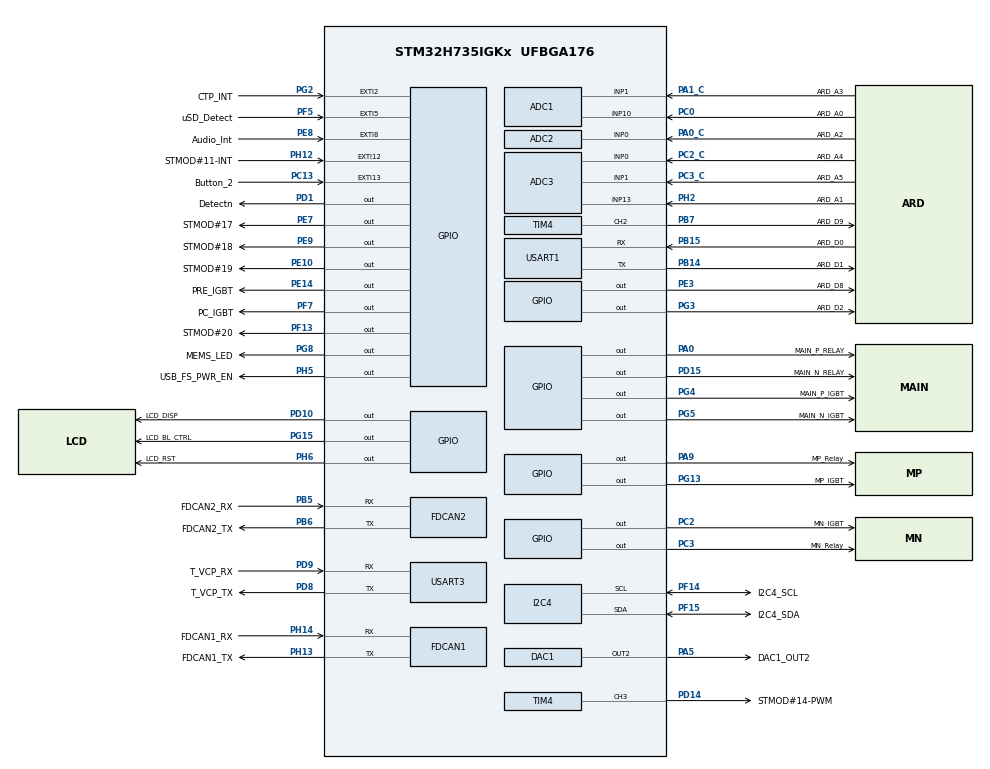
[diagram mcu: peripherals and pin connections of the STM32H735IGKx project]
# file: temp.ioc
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ADC1.Channel-1\#ChannelRegularConversion=ADC_CHANNEL_1
ADC1.NbrOfConversionFlag=1
ADC1.OffsetNumber-1\#ChannelRegularConversion=ADC_OFFSET_NONE
ADC1.OffsetSignedSaturation-1\#ChannelRegularConversion=DISABLE
ADC1.Rank-1\#ChannelRegularConversion=1
ADC1.SamplingTime-1\#ChannelRegularConversion=ADC_SAMPLETIME_1CYCLE_5
ADC1.master=1
ADC2.Channel-0\#ChannelRegularConversion=ADC_CHANNEL_0
ADC2.NbrOfConversionFlag=1
ADC2.OffsetNumber-0\#ChannelRegularConversion=ADC_OFFSET_NONE
ADC2.OffsetSignedSaturation-0\#ChannelRegularConversion=DISABLE
ADC2.Rank-0\#ChannelRegularConversion=1
ADC2.SamplingTime-0\#ChannelRegularConversion=ADC_SAMPLETIME_1CYCLE_5
ADC3.Channel-2\#ChannelRegularConversion=ADC_CHANNEL_0
ADC3.NbrOfConversionFlag=1
ADC3.OffsetNumber-2\#ChannelRegularConversion=ADC_OFFSET_NONE
ADC3.OffsetSaturation-2\#ChannelRegularConversion=DISABLE
ADC3.OffsetSign-2\#ChannelRegularConversion=ADC3_OFFSET_SIGN_NEGATIVE
ADC3.OffsetSignedSaturation-2\#ChannelRegularConversion=DISABLE
ADC3.Rank-2\#ChannelRegularConversion=1
ADC3.SamplingTime-2\#ChannelRegularConversion=ADC3_SAMPLETIME_2CYCLES_5
DAC1.DAC_Channel-DAC_OUT2=DAC_CHANNEL_2
I2C4.Timing=0x60404E72
Mcu.Family=STM32H7
Mcu.Name=STM32H735IGKx
Mcu.Package=UFBGA176
NVIC.EXTI15_10_IRQn=true\:0\:0\:false\:false\:true\:true\:true
NVIC.PriorityGroup=NVIC_PRIORITYGROUP_4
NVIC.TIM16_IRQn=true\:0\:0\:false\:false\:true\:true\:true
NVIC.TIM17_IRQn=true\:0\:0\:false\:false\:true\:true\:true
NVIC.TIM7_IRQn=true\:0\:0\:false\:false\:true\:true\:true
NVIC.TIM8_UP_TIM13_IRQn=true\:0\:0\:false\:false\:true\:true\:true
PA0.GPIO_Label=MAIN_P_RELAY
PA0.Signal=GPIO_Output
PA0_C.GPIO_Label=ARD_A2
PA0_C.Signal=ADCx_INP0
PA1.GPIO_Label=RMII_REF_CLK
PA1.GPIO_Speed=GPIO_SPEED_FREQ_LOW
PA1.Signal=ETH_REF_CLK
PA10.GPIO_Label=USB_FS_ID
PA10.Signal=USB_OTG_HS_ID
PA11.GPIO_Label=USB_FS_DM
PA11.Signal=USB_OTG_HS_DM
PA12.GPIO_Label=USB_FS_DP
PA12.Signal=USB_OTG_HS_DP
PA13(JTMS/SWDIO).GPIO_Label=JTMS
PA13(JTMS/SWDIO).Mode=JTAG_5_pins
PA13(JTMS/SWDIO).Signal=DEBUG_JTMS-SWDIO
PA14(JTCK/SWCLK).GPIO_Label=JTCK
PA14(JTCK/SWCLK).Mode=JTAG_5_pins
PA14(JTCK/SWCLK).Signal=DEBUG_JTCK-SWCLK
PA15(JTDI).GPIO_Label=JTDI
PA15(JTDI).Mode=JTAG_5_pins
PA15(JTDI).Signal=DEBUG_JTDI
PA1_C.GPIO_Label=ARD_A3
PA1_C.Signal=ADCx_INP1
PA2.GPIO_Label=RMII_MDIO
PA2.GPIO_Speed=GPIO_SPEED_FREQ_LOW
PA2.Signal=ETH_MDIO
PA3.GPIO_Label=LCD_B5
PA3.GPIO_Speed=GPIO_SPEED_FREQ_LOW
PA3.Signal=LTDC_B5
PA4.GPIO_Label=LCD_VSYNC
PA4.GPIO_Speed=GPIO_SPEED_FREQ_LOW
PA4.Signal=LTDC_VSYNC
PA5.GPIO_Label=DAC1_OUT2
PA5.Signal=COMP_DAC12_group
PA7.GPIO_Label=RMII_CRS_DV
PA7.GPIO_Speed=GPIO_SPEED_FREQ_LOW
PA7.Signal=ETH_CRS_DV
PA8.GPIO_Label=LCD_B3
PA8.GPIO_Speed=GPIO_SPEED_FREQ_LOW
PA8.Signal=LTDC_B3
PA9.GPIO_Label=MP_Relay
PA9.Signal=GPIO_Output
PB0.GPIO_Label=LCD_G1
PB0.GPIO_Speed=GPIO_SPEED_FREQ_LOW
PB0.Signal=LTDC_G1
PB1.GPIO_Label=LCD_G0
PB1.GPIO_Speed=GPIO_SPEED_FREQ_LOW
PB1.Signal=LTDC_G0
PB10.GPIO_Label=RMII_RX_ER
PB10.Signal=ETH_RX_ER
PB11.GPIO_Label=RMII_TX_EN
PB11.GPIO_Speed=GPIO_SPEED_FREQ_LOW
PB11.Signal=ETH_TX_EN
PB12.GPIO_Label=RMII_TXD0
PB12.GPIO_Speed=GPIO_SPEED_FREQ_LOW
PB12.Signal=ETH_TXD0
PB13.GPIO_Label=RMII_TXD1
PB13.GPIO_Speed=GPIO_SPEED_FREQ_LOW
PB13.Signal=ETH_TXD1
PB14.GPIO_Label=ARD_D1
PB14.GPIO_PuPd=GPIO_NOPULL
PB14.Mode=Asynchronous
PB14.Signal=USART1_TX
PB15.GPIO_Label=ARD_D0
PB15.GPIO_PuPd=GPIO_NOPULL
PB15.Mode=Asynchronous
PB15.Signal=USART1_RX
PB2.GPIO_Label=OCSPI1_DQS
PB2.Signal=OCTOSPIM_P1_DQS
PB3(JTDO/TRACESWO).GPIO_Label=JTDO
PB3(JTDO/TRACESWO).Mode=JTAG_5_pins
PB3(JTDO/TRACESWO).Signal=DEBUG_JTDO-SWO
PB4(NJTRST).GPIO_Label=NJTRST
PB4(NJTRST).Mode=JTAG_5_pins
PB4(NJTRST).Signal=DEBUG_JTRST
PB5.GPIO_Label=FDCAN2_RX
PB5.Mode=FDCAN_Activate
PB5.Signal=FDCAN2_RX
PB6.GPIO_Label=FDCAN2_TX
PB6.Mode=FDCAN_Activate
PB6.Signal=FDCAN2_TX
PB7.GPIO_Label=ARD_D9
PB7.Signal=S_TIM4_CH2
PB8.GPIO_Label=LCD_B6
PB8.GPIO_Speed=GPIO_SPEED_FREQ_LOW
PB8.Signal=LTDC_B6
PB9.GPIO_Label=LCD_B7
PB9.GPIO_Speed=GPIO_SPEED_FREQ_LOW
PB9.Signal=LTDC_B7
PC0.GPIO_Label=ARD_A0
PC0.Signal=ADCx_INP10
PC1.GPIO_Label=RMII_MDC
PC1.GPIO_Speed=GPIO_SPEED_FREQ_LOW
PC1.Signal=ETH_MDC
PC10.GPIO_Label=SDIO1_D2
PC10.Signal=SDMMC1_D2
PC11.GPIO_Label=SDIO1_D3
PC11.Signal=SDMMC1_D3
PC12.GPIO_Label=SDIO1_CK
PC12.Signal=SDMMC1_CK
PC13.GPIO_Label=Button_2
PC13.Signal=GPXTI13
PC14-OSC32_IN.Mode=LSE-External-Oscillator
PC14-OSC32_IN.Signal=RCC_OSC32_IN
PC15-OSC32_OUT.Mode=LSE-External-Oscillator
PC15-OSC32_OUT.Signal=RCC_OSC32_OUT
PC2.GPIO_Label=MN_IGBT
PC2.Signal=GPIO_Output
PC2_C.GPIO_Label=ARD_A4
PC2_C.Mode=IN0-Single-Ended
PC2_C.Signal=ADC3_INP0
PC3.GPIO_Label=MN_Relay
PC3.Signal=GPIO_Output
PC3_C.GPIO_Label=ARD_A5
PC3_C.Mode=IN1-Single-Ended
PC3_C.Signal=ADC3_INP1
PC4.GPIO_Label=RMII_RXD0
PC4.GPIO_Speed=GPIO_SPEED_FREQ_LOW
PC4.Signal=ETH_RXD0
PC5.GPIO_Label=RMII_RXD1
PC5.GPIO_Speed=GPIO_SPEED_FREQ_LOW
PC5.Signal=ETH_RXD1
PC6.GPIO_Label=LCD_HSYNC
PC6.GPIO_Speed=GPIO_SPEED_FREQ_LOW
PC6.Signal=LTDC_HSYNC
PC7.GPIO_Label=LCD_G6
PC7.GPIO_Speed=GPIO_SPEED_FREQ_LOW
PC7.Signal=LTDC_G6
PC8.GPIO_Label=SDIO1_D0
PC8.Signal=SDMMC1_D0
PC9.GPIO_Label=SDIO1_D1
PC9.Signal=SDMMC1_D1
PD0.GPIO_Label=LCD_B1
PD0.GPIO_Speed=GPIO_SPEED_FREQ_LOW
PD0.Signal=LTDC_B1
PD1.GPIO_Label=Detectn
PD1.GPIO_PuPd=GPIO_NOPULL
PD1.Signal=GPIO_Output
PD10.GPIO_Label=LCD_DISP
PD10.GPIO_Speed=GPIO_SPEED_FREQ_LOW
PD10.Signal=GPIO_Output
PD11.GPIO_Label=OCSPI1_IO0
PD11.Signal=OCTOSPIM_P1_IO0
PD12.GPIO_Label=OCSPI1_IO1
PD12.Signal=OCTOSPIM_P1_IO1
PD13.GPIO_Label=OCSPI1_IO3
PD13.Signal=OCTOSPIM_P1_IO3
PD14.GPIO_Label=STMOD\#14-PWM
PD14.Signal=S_TIM4_CH3
PD15.GPIO_Label=MAIN_N_RELAY
PD15.Signal=GPIO_Output
PD2.GPIO_Label=SDIO1_CMD
PD2.Signal=SDMMC1_CMD
PD3.GPIO_Label=LCD_G7
PD3.GPIO_Speed=GPIO_SPEED_FREQ_LOW
PD3.Signal=LTDC_G7
PD4.GPIO_Label=OCSPI1_IO4
PD4.Signal=OCTOSPIM_P1_IO4
PD5.GPIO_Label=OCSPI1_IO5
PD5.Signal=OCTOSPIM_P1_IO5
PD6.GPIO_Label=LCD_B2
PD6.GPIO_Speed=GPIO_SPEED_FREQ_LOW
PD6.Signal=LTDC_B2
PD7.GPIO_Label=OCSPI1_IO7
PD7.Signal=OCTOSPIM_P1_IO7
PD8.GPIO_Label=T_VCP_TX
PD8.GPIO_PuPd=GPIO_NOPULL
PD8.Mode=Asynchronous
PD8.Signal=USART3_TX
PD9.GPIO_Label=T_VCP_RX
PD9.GPIO_PuPd=GPIO_NOPULL
PD9.Mode=Asynchronous
PD9.Signal=USART3_RX
PE0.GPIO_Label=LCD_R0
PE0.GPIO_Speed=GPIO_SPEED_FREQ_LOW
PE0.Signal=LTDC_R0
PE1.GPIO_Label=LCD_R6
PE1.GPIO_Speed=GPIO_SPEED_FREQ_LOW
PE1.Signal=LTDC_R6
PE10.GPIO_Label=STMOD\#19
PE10.Signal=GPIO_Output
PE11.GPIO_Label=LCD_G3
PE11.GPIO_Speed=GPIO_SPEED_FREQ_LOW
PE11.Signal=LTDC_G3
PE12.GPIO_Label=LCD_B4
PE12.GPIO_Speed=GPIO_SPEED_FREQ_LOW
PE12.Signal=LTDC_B4
PE13.GPIO_Label=LCD_DE
PE13.GPIO_Speed=GPIO_SPEED_FREQ_LOW
PE13.Signal=LTDC_DE
PE14.GPIO_Label=PRE_IGBT
PE14.Signal=GPIO_Output
PE15.GPIO_Label=LCD_R7
PE15.GPIO_Speed=GPIO_SPEED_FREQ_LOW
PE15.Signal=LTDC_R7
PE2.GPIO_Label=OCSPI1_IO2
PE2.Signal=OCTOSPIM_P1_IO2
PE3.GPIO_Label=ARD_D8
PE3.Signal=GPIO_Output
PE4.GPIO_Label=SAI4_D2
PE4.Signal=SAI4_D2
PE5.GPIO_Label=SAI4_CK2
PE5.Signal=SAI4_CK2
PE6.GPIO_Label=SAI1_SD_A
PE6.Signal=SAI1_SD_A
PE7.GPIO_Label=STMOD\#17
PE7.Signal=GPIO_Output
PE8.GPIO_Label=Audio_Int
PE8.Signal=GPXTI8
PE9.GPIO_Label=STMOD\#18
PE9.Signal=GPIO_Output
PF0.GPIO_Label=OCSPI2_IO0
PF0.Signal=OCTOSPIM_P2_IO0
PF1.GPIO_Label=OCSPI2_IO1
PF1.Signal=OCTOSPIM_P2_IO1
PF10.GPIO_Label=OCSPI1_CLK
PF10.Signal=OCTOSPIM_P1_CLK
PF11.GPIO_Label=SPI5_MOSI
PF11.Signal=SPI5_MOSI
PF12.GPIO_Label=OCSPI2_DQS
PF12.Signal=OCTOSPIM_P2_DQS
PF13.GPIO_Label=STMOD\#20
PF13.Signal=GPIO_Output
PF14.GPIO_Label=I2C4_SCL
PF14.GPIO_Pu=GPIO_PULLUP
PF14.Mode=I2C
PF14.Signal=I2C4_SCL
PF15.GPIO_Label=I2C4_SDA
PF15.GPIO_Pu=GPIO_PULLUP
PF15.Mode=I2C
PF15.Signal=I2C4_SDA
PF2.GPIO_Label=OCSPI2_IO2
PF2.Signal=OCTOSPIM_P2_IO2
PF3.GPIO_Label=OCSPI2_IO3
PF3.Signal=OCTOSPIM_P2_IO3
PF4.GPIO_Label=OCSPI2_CLK
PF4.Signal=OCTOSPIM_P2_CLK
PF5.GPIO_Label=uSD_Detect
PF5.Signal=GPXTI5
PF6.GPIO_Label=SAI1_SD_B
PF6.Signal=SAI1_SD_B
PF7.GPIO_Label=PC_IGBT
PF7.Signal=GPIO_Output
PF8.GPIO_Label=SAI1_SCK_B
PF8.Signal=SAI1_SCK_B
PF9.GPIO_Label=SAI1_FS_B
PF9.Signal=SAI1_FS_B
PG0.GPIO_Label=OCSPI2_IO4
PG0.Signal=OCTOSPIM_P2_IO4
PG1.GPIO_Label=OCSPI2_IO5
PG1.Signal=OCTOSPIM_P2_IO5
PG10.GPIO_Label=OCSPI2_IO6
PG10.Signal=OCTOSPIM_P2_IO6
PG11.GPIO_Label=OCSPI2_IO7
PG11.Signal=OCTOSPIM_P2_IO7
PG12.GPIO_Label=OCSPI2_NCS
PG12.Signal=OCTOSPIM_P2_NCS
PG13.GPIO_Label=MP_IGBT
PG13.Signal=GPIO_Output
PG14.GPIO_Label=LCD_B0
PG14.GPIO_Speed=GPIO_SPEED_FREQ_LOW
PG14.Signal=LTDC_B0
PG15.GPIO_Label=LCD_BL_CTRL
PG15.GPIO_Speed=GPIO_SPEED_FREQ_LOW
PG15.Signal=GPIO_Output
PG2.GPIO_Label=CTP_INT
PG2.Signal=GPXTI2
PG3.GPIO_Label=ARD_D2
PG3.Signal=GPIO_Output
PG4.GPIO_Label=MAIN_P_IGBT
PG4.Signal=GPIO_Output
PG5.GPIO_Label=MAIN_N_IGBT
PG5.Signal=GPIO_Output
PG6.GPIO_Label=OCSPI1_NCS
PG6.Signal=OCTOSPIM_P1_NCS
PG7.GPIO_Label=LCD_CLK
PG7.GPIO_Speed=GPIO_SPEED_FREQ_LOW
PG7.Signal=LTDC_CLK
PG8.GPIO_Label=MEMS_LED
PG8.Signal=GPIO_Output
PG9.GPIO_Label=OCSPI1_IO6
PG9.Signal=OCTOSPIM_P1_IO6
PH0-OSC_IN.Mode=HSE-External-Oscillator
PH0-OSC_IN.Signal=RCC_OSC_IN
PH1-OSC_OUT.Mode=HSE-External-Oscillator
PH1-OSC_OUT.Signal=RCC_OSC_OUT
PH10.GPIO_Label=LCD_R4
PH10.GPIO_Speed=GPIO_SPEED_FREQ_LOW
PH10.Signal=LTDC_R4
PH11.GPIO_Label=LCD_R5
PH11.GPIO_Speed=GPIO_SPEED_FREQ_LOW
PH11.Signal=LTDC_R5
PH12.GPIO_Label=STMOD\#11-INT
PH12.Signal=GPXTI12
PH13.GPIO_Label=FDCAN1_TX
PH13.Mode=FDCAN_Activate
PH13.Signal=FDCAN1_TX
PH14.GPIO_Label=FDCAN1_RX
PH14.Mode=FDCAN_Activate
PH14.Signal=FDCAN1_RX
PH15.GPIO_Label=LCD_G4
PH15.GPIO_Speed=GPIO_SPEED_FREQ_LOW
PH15.Signal=LTDC_G4
PH2.GPIO_Label=ARD_A1
PH2.Mode=IN13-Single-Ended
PH2.Signal=ADC3_INP13
PH3.GPIO_Label=LCD_R1
PH3.GPIO_Speed=GPIO_SPEED_FREQ_LOW
PH3.Signal=LTDC_R1
PH4.GPIO_Label=LCD_G5
PH4.GPIO_Speed=GPIO_SPEED_FREQ_LOW
PH4.Signal=LTDC_G5
PH5.GPIO_Label=USB_FS_PWR_EN
PH5.Signal=GPIO_Output
PH6.GPIO_Label=LCD_RST
PH6.GPIO_Speed=GPIO_SPEED_FREQ_LOW
PH6.Signal=GPIO_Output
PH7.GPIO_Label=SPI5_MISO
PH7.Signal=SPI5_MISO
PH8.GPIO_Label=LCD_R2
PH8.GPIO_Speed=GPIO_SPEED_FREQ_LOW
PH8.Signal=LTDC_R2
PH9.GPIO_Label=LCD_R3
PH9.GPIO_Speed=GPIO_SPEED_FREQ_LOW
PH9.Signal=LTDC_R3
ProjectManager.HeapSize=0x200
ProjectManager.StackSize=0x400
ProjectManager.TargetToolchain=STM32CubeIDE
RCC.ADCFreq_Value=80000000
RCC.APB1Freq_Value=137500000
RCC.APB2Freq_Value=137500000
RCC.APB3Freq_Value=137500000
RCC.APB4Freq_Value=137500000
RCC.CortexFreq_Value=550000000
RCC.D1PPRE=RCC_APB3_DIV2
RCC.D2PPRE1=RCC_APB1_DIV2
RCC.D2PPRE2=RCC_APB2_DIV2
RCC.D3PPRE=RCC_APB4_DIV2
RCC.DIVM1=5
RCC.DIVM2=5
RCC.DIVN1=110
RCC.DIVN2=80
RCC.DIVP1=1
RCC.DIVP2=5
RCC.DIVQ1=4
RCC.HCLKFreq_Value=275000000
RCC.HPRE=RCC_HCLK_DIV2
RCC.PLL2FRACN=0
RCC.PLL3FRACN=0
RCC.PLLFRACN=0
RCC.PLLSourceVirtual=RCC_PLLSOURCE_HSE
RCC.SYSCLKFreq_VALUE=550000000
RCC.SYSCLKSource=RCC_SYSCLKSOURCE_PLLCLK
RCC.USBCLockSelection=RCC_USBCLKSOURCE_HSI48
RCC.USBFreq_Value=48000000
RTC.Date=10
RTC.Hours=22
RTC.Minutes=22
RTC.Month=RTC_MONTH_FEBRUARY
RTC.Seconds=22
RTC.WeekDay=RTC_WEEKDAY_THURSDAY
RTC.Year=22
SH.ADCx_INP0.0=ADC1_INP0
SH.ADCx_INP0.1=ADC2_INP0,IN0-Single-Ended
SH.ADCx_INP1.0=ADC2_INP1
SH.ADCx_INP1.1=ADC1_INP1,IN1-Single-Ended
SH.ADCx_INP10.0=ADC1_INP10,IN10-Single-Ended
SH.COMP_DAC12_group.0=DAC1_OUT2,DAC_OUT2
SH.S_TIM4_CH2.0=TIM4_CH2,PWM Generation2 CH2
SH.S_TIM4_CH3.0=TIM4_CH3,PWM Generation3 CH3
TIM13.Period=1500-1
TIM13.Prescaler=27500 -1
TIM14.Prescaler=2750-1
TIM16.Period=3500-1
TIM16.Prescaler=27500-1
TIM17.Period=5000-1
TIM17.Prescaler=27500-1
TIM4.Channel-PWM\ Generation2\ CH2=TIM_CHANNEL_2
TIM4.Channel-PWM\ Generation3\ CH3=TIM_CHANNEL_3
TIM7.Period=500-1
TIM7.Prescaler=27500-1
USART1.VirtualMode-Asynchronous=VM_ASYNC
USART3.VirtualMode-Asynchronous=VM_ASYNC
VP_RTC_VS_RTC_Activate.Mode=RTC_Enabled
VP_RTC_VS_RTC_Calendar.Mode=RTC_Calendar
VP_TIM13_VS_ClockSourceINT.Mode=Enable_Timer
VP_TIM14_VS_ClockSourceINT.Mode=Enable_Timer
VP_TIM16_VS_ClockSourceINT.Mode=Enable_Timer
VP_TIM17_VS_ClockSourceINT.Mode=Enable_Timer
VP_TIM7_VS_ClockSourceINT.Mode=Enable_Timer
board=STM32H735G-DK

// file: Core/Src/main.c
/* USER CODE BEGIN Header */
/**
  ******************************************************************************
  * @file           : main.c
  * @brief          : Main program body
  ******************************************************************************
  * @attention
  *
  * <h2><center>&copy; Copyright (c) 2022 STMicroelectronics.
  * All rights reserved.</center></h2>
  *
  * This software component is licensed by ST under BSD 3-Clause license,
  * the "License"; You may not use this file except in compliance with the
  * License. You may obtain a copy of the License at:
  *                        opensource.org/licenses/BSD-3-Clause
  *
  ******************************************************************************
  */
/* USER CODE END Header */
#include "main.h"

/* USER CODE BEGIN PD */
#ifdef __GNUC__
/* With GCC, small printf (option LD Linker->Libraries->Small printf
   set to 'Yes') calls __io_putchar() */
#define PUTCHAR_PROTOTYPE int __io_putchar(int ch)
#else
#define PUTCHAR_PROTOTYPE int fputc(int ch, FILE *f)
#endif /* __GNUC__ */

#define FIX_TIMER_TRIGGER(handle_ptr) (__HAL_TIM_CLEAR_FLAG(handle_ptr, TIM_SR_UIF))

#define MN_ON 0
#define MP_ON 1
#define OFF 2
/* USER CODE END PD */

ADC_HandleTypeDef hadc1;
ADC_HandleTypeDef hadc2;
ADC_HandleTypeDef hadc3;

DAC_HandleTypeDef hdac1;

FDCAN_HandleTypeDef hfdcan1;
FDCAN_HandleTypeDef hfdcan2;

I2C_HandleTypeDef hi2c4;

RTC_HandleTypeDef hrtc;

TIM_HandleTypeDef htim4;
TIM_HandleTypeDef htim7;
TIM_HandleTypeDef htim13;
TIM_HandleTypeDef htim14;
TIM_HandleTypeDef htim16;
TIM_HandleTypeDef htim17;

UART_HandleTypeDef huart1;
UART_HandleTypeDef huart3;

/* USER CODE BEGIN PV */
PUTCHAR_PROTOTYPE
{
  /* Place your implementation of fputc here */
  /* e.g. write a character to the USART1 and Loop until the end of transmission */
  HAL_UART_Transmit(&huart3, (uint8_t *)&ch, 1, 0xFFFF);

  return ch;
}

//volatile unsigned int timing_counter = 0; // for timing control in autostart, stop

// status variables
int tim7_status; // check if mp relay on/mn relay on/mp,mn relay off
int signal_status = 1; // check if on(auto_start)/off(stop) signal

// variables for printing the timing logs
uint32_t timestamp[2000][2];
uint32_t id = 0; // timestamp arr index

/* USER CODE END PV */

void SystemClock_Config(void);
void PeriphCommonClock_Config(void);
static void MX_GPIO_Init(void);
static void MX_ADC1_Init(void);
static void MX_ADC2_Init(void);
static void MX_ADC3_Init(void);
static void MX_DAC1_Init(void);
static void MX_FDCAN1_Init(void);
static void MX_FDCAN2_Init(void);
static void MX_I2C4_Init(void);
static void MX_TIM4_Init(void);
static void MX_USART1_UART_Init(void);
static void MX_USART3_UART_Init(void);
static void MX_TIM13_Init(void);
static void MX_RTC_Init(void);
static void MX_TIM14_Init(void);
static void MX_TIM7_Init(void);
static void MX_TIM16_Init(void);
static void MX_TIM17_Init(void);

/* USER CODE BEGIN 0 */

// save current tim14 cnt with given sequence step(x)
void save_timestamp(int x){
	timestamp[id][0] = x;
	timestamp[id][1] = TIM14->CNT / 100;
	//timestamp[id] = uwTick;
	id++;
}

// print the timestamps saved before
void print_timestamp(){
	int i, tmp;
	int k = 0;
	i = 0;
	for (i=0; i<id; i++){
		// when cnt is overflowed
		if (timestamp[i][1] <= timestamp[i-1][1])
			tmp = 65535 + timestamp[i][1] - timestamp[i-1][1];
		else
			tmp = timestamp[i][1] - timestamp[i-1][1];
		printf("(%d) %ld ms ellapsed after prev timestamp. \r\n", timestamp[i][0], tmp);
		printf("--------------------\r\n");
	}

}

//void autostart(){
//	if(timing_counter == 0){
//		HAL_GPIO_WritePin(GPIOC, MN_IGBT_Pin, RESET);
//		TIM14->CNT = 0;
//		HAL_TIM_Base_Start(&htim14);
//	}
//	else if(timing_counter == 1){
//		HAL_GPIO_WritePin(GPIOC, MN_Relay_Pin, RESET);
//		save_timestamp();
//	}
//	else if(timing_counter == 10){
//		HAL_GPIO_WritePin(GPIOF, PC_IGBT_Pin, SET);
//		save_timestamp();
//	}
//	else if(timing_counter == 20){
//		HAL_GPIO_WritePin(GPIOG, MP_IGBT_Pin, RESET);
//		save_timestamp();
//	}
//	else if(timing_counter == 21){
//		HAL_GPIO_WritePin(GPIOA, MP_Relay_Pin, SET);
//		save_timestamp();
//	}
//	else if(timing_counter == 30){
//		HAL_GPIO_WritePin(GPIOF, PC_IGBT_Pin, RESET);
//		save_timestamp();
//		HAL_TIM_Base_Stop_IT(&htim13);
//		HAL_TIM_Base_Stop(&htim14);
//		timing_counter = -1;
//		print_timestamp();
//		id = 0;
//	}
//	timing_counter += 1;
//}

// timers interrupt handler routine
void HAL_TIM_PeriodElapsedCallback(TIM_HandleTypeDef *htim)
{
	if (htim->Instance == TIM7){
		switch(tim7_status){
			case MN_ON: // mn relay on
				HAL_TIM_Base_Stop_IT(&htim7);
				HAL_GPIO_WritePin(GPIOC, MN_Relay_Pin, RESET);
				HAL_GPIO_WritePin(MAIN_N_RELAY_GPIO_Port, MAIN_N_RELAY_Pin, SET);
				save_timestamp(0);
				tim7_status = MP_ON; // toggle timer status
				break;
			case MP_ON: // mp relay on
				HAL_TIM_Base_Stop_IT(&htim7);
				HAL_GPIO_WritePin(GPIOA, MP_Relay_Pin, SET);
				HAL_GPIO_WritePin(MAIN_P_RELAY_GPIO_Port, MAIN_P_RELAY_Pin, SET);
				save_timestamp(3);
				break;
			case OFF: // mn, mp igbt off
				HAL_TIM_Base_Stop_IT(&htim7);
				HAL_GPIO_WritePin(GPIOC, MN_IGBT_Pin, SET);
				HAL_GPIO_WritePin(MAIN_N_IGBT_GPIO_Port, MAIN_N_IGBT_Pin, RESET);
				HAL_GPIO_WritePin(GPIOG, MP_IGBT_Pin, SET);
				HAL_GPIO_WritePin(MAIN_P_IGBT_GPIO_Port, MAIN_P_IGBT_Pin, RESET);

				save_timestamp(5);
				HAL_TIM_Base_Stop(&htim14);
				print_timestamp();
				id = 0; // reset the timestamp id
		}

	}
	else if (htim->Instance == TIM13){ // pc igbt on
		HAL_TIM_Base_Stop_IT(&htim13);
		HAL_GPIO_WritePin(GPIOF, PC_IGBT_Pin, SET);
		HAL_GPIO_WritePin(PRE_IGBT_GPIO_Port, PRE_IGBT_Pin, SET);

		save_timestamp(1);
	}
	else if (htim->Instance == TIM16){ // mp igbt on
		HAL_TIM_Base_Stop_IT(&htim16);
		HAL_GPIO_WritePin(GPIOG, MP_IGBT_Pin, RESET);
		HAL_GPIO_WritePin(MAIN_P_IGBT_GPIO_Port, MAIN_P_IGBT_Pin, SET);

		save_timestamp(2);
		TIM7->CNT = 0; // reset tim 7 for precise timing(50ms)
		FIX_TIMER_TRIGGER(&htim7); // start timer mp relay on
		HAL_TIM_Base_Start_IT(&htim7);
	}
	else if (htim->Instance == TIM17){ // pc igbt off
		HAL_TIM_Base_Stop_IT(&htim17);
		HAL_GPIO_WritePin(GPIOF, PC_IGBT_Pin, RESET);
		HAL_GPIO_WritePin(PRE_IGBT_GPIO_Port, PRE_IGBT_Pin, RESET);

		save_timestamp(4);
		HAL_TIM_Base_Stop(&htim14);
		print_timestamp();
		id = 0; // reset the timestamp id
	}
}

// interrupt routine for user button pushed
void HAL_GPIO_EXTI_Callback(uint16_t GPIO_Pin){

	if(GPIO_Pin == Button_2_Pin){
		// turn on the timer for checking timing
		TIM14->CNT = 0;
		HAL_TIM_Base_Start(&htim14);
		// if cur signal == auto_start
		if (signal_status){
			// turn on mn igbt
			HAL_GPIO_WritePin(GPIOC, MN_IGBT_Pin, RESET);
			HAL_GPIO_WritePin(MAIN_N_IGBT_GPIO_Port, MAIN_N_IGBT_Pin, SET);

			tim7_status = MN_ON;
			// turn on mn relay
			FIX_TIMER_TRIGGER(&htim7);
			HAL_TIM_Base_Start_IT(&htim7);
			// turn on pc igbt
			FIX_TIMER_TRIGGER(&htim13);
			HAL_TIM_Base_Start_IT(&htim13);
			// turn on mp igbt
			FIX_TIMER_TRIGGER(&htim16);
			HAL_TIM_Base_Start_IT(&htim16);
			// turn off pc relay
			FIX_TIMER_TRIGGER(&htim17);
			HAL_TIM_Base_Start_IT(&htim17);
		}
		// if cur signal == stop
		else if (!signal_status){
			// turn off mn relay, mp relay
			HAL_GPIO_WritePin(GPIOC, MN_Relay_Pin, SET);
			HAL_GPIO_WritePin(MAIN_N_RELAY_GPIO_Port, MAIN_N_RELAY_Pin, RESET);
			HAL_GPIO_WritePin(GPIOA, MP_Relay_Pin, RESET);
			HAL_GPIO_WritePin(MAIN_P_RELAY_GPIO_Port, MAIN_P_RELAY_Pin, RESET);
			// turn off mn igbt, mp igbt
			tim7_status = OFF;
			TIM7->CNT = 0; // reset tim 7 for precise timing(50ms)
			FIX_TIMER_TRIGGER(&htim7);
			HAL_TIM_Base_Start_IT(&htim7);
		}
		// toggle the signal_status (temporary)
		signal_status = !signal_status;
	}
}
/* USER CODE END 0 */

int main(void)
{

  /* MCU Configuration--------------------------------------------------------*/

  /* Reset of all peripherals, Initializes the Flash interface and the Systick. */
  HAL_Init();

  /* Configure the system clock */
  SystemClock_Config();

/* Configure the peripherals common clocks */
  PeriphCommonClock_Config();

  /* Initialize all configured peripherals */
  MX_GPIO_Init();
  MX_ADC1_Init();
  MX_ADC2_Init();
  MX_ADC3_Init();
  MX_DAC1_Init();
  MX_FDCAN1_Init();
  MX_FDCAN2_Init();
  MX_I2C4_Init();
  MX_TIM4_Init();
  MX_USART1_UART_Init();
  MX_USART3_UART_Init();
  MX_TIM13_Init();
  MX_RTC_Init();
  MX_TIM14_Init();
  MX_TIM7_Init();
  MX_TIM16_Init();
  MX_TIM17_Init();

  /* Infinite loop */
  /* USER CODE BEGIN WHILE */
  HAL_GPIO_WritePin(GPIOC, MN_IGBT_Pin, SET);
  HAL_GPIO_WritePin(GPIOC, MN_Relay_Pin, SET);
  HAL_GPIO_WritePin(GPIOG, MP_IGBT_Pin, SET);

  while (1)
  {
    /* USER CODE END WHILE */

  }
}

void SystemClock_Config(void)
{
  RCC_OscInitTypeDef RCC_OscInitStruct = {0};
  RCC_ClkInitTypeDef RCC_ClkInitStruct = {0};

  /** Supply configuration update enable
  */
  HAL_PWREx_ConfigSupply(PWR_DIRECT_SMPS_SUPPLY);
  /** Configure the main internal regulator output voltage
  */
  __HAL_PWR_VOLTAGESCALING_CONFIG(PWR_REGULATOR_VOLTAGE_SCALE0);

  while(!__HAL_PWR_GET_FLAG(PWR_FLAG_VOSRDY)) {}
  /** Macro to configure the PLL clock source
  */
  __HAL_RCC_PLL_PLLSOURCE_CONFIG(RCC_PLLSOURCE_HSE);
  /** Initializes the RCC Oscillators according to the specified parameters
  * in the RCC_OscInitTypeDef structure.
  */
  RCC_OscInitStruct.OscillatorType = RCC_OSCILLATORTYPE_LSI|RCC_OSCILLATORTYPE_HSE;
  RCC_OscInitStruct.HSEState = RCC_HSE_ON;
  RCC_OscInitStruct.LSIState = RCC_LSI_ON;
  RCC_OscInitStruct.PLL.PLLState = RCC_PLL_ON;
  RCC_OscInitStruct.PLL.PLLSource = RCC_PLLSOURCE_HSE;
  RCC_OscInitStruct.PLL.PLLM = 5;
  RCC_OscInitStruct.PLL.PLLN = 110;
  RCC_OscInitStruct.PLL.PLLP = 1;
  RCC_OscInitStruct.PLL.PLLQ = 4;
  RCC_OscInitStruct.PLL.PLLR = 2;
  RCC_OscInitStruct.PLL.PLLRGE = RCC_PLL1VCIRANGE_2;
  RCC_OscInitStruct.PLL.PLLVCOSEL = RCC_PLL1VCOWIDE;
  RCC_OscInitStruct.PLL.PLLFRACN = 0;
  if (HAL_RCC_OscConfig(&RCC_OscInitStruct) != HAL_OK)
  {
    Error_Handler();
  }
  /** Initializes the CPU, AHB and APB buses clocks
  */
  RCC_ClkInitStruct.ClockType = RCC_CLOCKTYPE_HCLK|RCC_CLOCKTYPE_SYSCLK
                              |RCC_CLOCKTYPE_PCLK1|RCC_CLOCKTYPE_PCLK2
                              |RCC_CLOCKTYPE_D3PCLK1|RCC_CLOCKTYPE_D1PCLK1;
  RCC_ClkInitStruct.SYSCLKSource = RCC_SYSCLKSOURCE_PLLCLK;
  RCC_ClkInitStruct.SYSCLKDivider = RCC_SYSCLK_DIV1;
  RCC_ClkInitStruct.AHBCLKDivider = RCC_HCLK_DIV2;
  RCC_ClkInitStruct.APB3CLKDivider = RCC_APB3_DIV2;
  RCC_ClkInitStruct.APB1CLKDivider = RCC_APB1_DIV2;
  RCC_ClkInitStruct.APB2CLKDivider = RCC_APB2_DIV2;
  RCC_ClkInitStruct.APB4CLKDivider = RCC_APB4_DIV2;

  if (HAL_RCC_ClockConfig(&RCC_ClkInitStruct, FLASH_LATENCY_3) != HAL_OK)
  {
    Error_Handler();
  }
}

void PeriphCommonClock_Config(void)
{
  RCC_PeriphCLKInitTypeDef PeriphClkInitStruct = {0};

  /** Initializes the peripherals clock
  */
  PeriphClkInitStruct.PeriphClockSelection = RCC_PERIPHCLK_ADC;
  PeriphClkInitStruct.PLL2.PLL2M = 5;
  PeriphClkInitStruct.PLL2.PLL2N = 80;
  PeriphClkInitStruct.PLL2.PLL2P = 5;
  PeriphClkInitStruct.PLL2.PLL2Q = 2;
  PeriphClkInitStruct.PLL2.PLL2R = 2;
  PeriphClkInitStruct.PLL2.PLL2RGE = RCC_PLL2VCIRANGE_2;
  PeriphClkInitStruct.PLL2.PLL2VCOSEL = RCC_PLL2VCOWIDE;
  PeriphClkInitStruct.PLL2.PLL2FRACN = 0;
  PeriphClkInitStruct.AdcClockSelection = RCC_ADCCLKSOURCE_PLL2;
  if (HAL_RCCEx_PeriphCLKConfig(&PeriphClkInitStruct) != HAL_OK)
  {
    Error_Handler();
  }
}

static void MX_ADC1_Init(void)
{

  ADC_MultiModeTypeDef multimode = {0};
  ADC_ChannelConfTypeDef sConfig = {0};

  /** Common config
  */
  hadc1.Instance = ADC1;
  hadc1.Init.ClockPrescaler = ADC_CLOCK_ASYNC_DIV1;
  hadc1.Init.Resolution = ADC_RESOLUTION_16B;
  hadc1.Init.ScanConvMode = ADC_SCAN_DISABLE;
  hadc1.Init.EOCSelection = ADC_EOC_SINGLE_CONV;
  hadc1.Init.LowPowerAutoWait = DISABLE;
  hadc1.Init.ContinuousConvMode = DISABLE;
  hadc1.Init.NbrOfConversion = 1;
  hadc1.Init.DiscontinuousConvMode = DISABLE;
  hadc1.Init.ExternalTrigConv = ADC_SOFTWARE_START;
  hadc1.Init.ExternalTrigConvEdge = ADC_EXTERNALTRIGCONVEDGE_NONE;
  hadc1.Init.ConversionDataManagement = ADC_CONVERSIONDATA_DR;
  hadc1.Init.Overrun = ADC_OVR_DATA_PRESERVED;
  hadc1.Init.LeftBitShift = ADC_LEFTBITSHIFT_NONE;
  hadc1.Init.OversamplingMode = DISABLE;
  if (HAL_ADC_Init(&hadc1) != HAL_OK)
  {
    Error_Handler();
  }
  /** Configure the ADC multi-mode
  */
  multimode.Mode = ADC_MODE_INDEPENDENT;
  if (HAL_ADCEx_MultiModeConfigChannel(&hadc1, &multimode) != HAL_OK)
  {
    Error_Handler();
  }
  /** Configure Regular Channel
  */
  sConfig.Channel = ADC_CHANNEL_1;
  sConfig.Rank = ADC_REGULAR_RANK_1;
  sConfig.SamplingTime = ADC_SAMPLETIME_1CYCLE_5;
  sConfig.SingleDiff = ADC_SINGLE_ENDED;
  sConfig.OffsetNumber = ADC_OFFSET_NONE;
  sConfig.Offset = 0;
  sConfig.OffsetSignedSaturation = DISABLE;
  if (HAL_ADC_ConfigChannel(&hadc1, &sConfig) != HAL_OK)
  {
    Error_Handler();
  }

}

static void MX_ADC2_Init(void)
{

  ADC_ChannelConfTypeDef sConfig = {0};

  /** Common config
  */
  hadc2.Instance = ADC2;
  hadc2.Init.ClockPrescaler = ADC_CLOCK_ASYNC_DIV1;
  hadc2.Init.Resolution = ADC_RESOLUTION_16B;
  hadc2.Init.ScanConvMode = ADC_SCAN_DISABLE;
  hadc2.Init.EOCSelection = ADC_EOC_SINGLE_CONV;
  hadc2.Init.LowPowerAutoWait = DISABLE;
  hadc2.Init.ContinuousConvMode = DISABLE;
  hadc2.Init.NbrOfConversion = 1;
  hadc2.Init.DiscontinuousConvMode = DISABLE;
  hadc2.Init.ExternalTrigConv = ADC_SOFTWARE_START;
  hadc2.Init.ExternalTrigConvEdge = ADC_EXTERNALTRIGCONVEDGE_NONE;
  hadc2.Init.ConversionDataManagement = ADC_CONVERSIONDATA_DR;
  hadc2.Init.Overrun = ADC_OVR_DATA_PRESERVED;
  hadc2.Init.LeftBitShift = ADC_LEFTBITSHIFT_NONE;
  hadc2.Init.OversamplingMode = DISABLE;
  if (HAL_ADC_Init(&hadc2) != HAL_OK)
  {
    Error_Handler();
  }
  /** Configure Regular Channel
  */
  sConfig.Channel = ADC_CHANNEL_0;
  sConfig.Rank = ADC_REGULAR_RANK_1;
  sConfig.SamplingTime = ADC_SAMPLETIME_1CYCLE_5;
  sConfig.SingleDiff = ADC_SINGLE_ENDED;
  sConfig.OffsetNumber = ADC_OFFSET_NONE;
  sConfig.Offset = 0;
  sConfig.OffsetSignedSaturation = DISABLE;
  if (HAL_ADC_ConfigChannel(&hadc2, &sConfig) != HAL_OK)
  {
    Error_Handler();
  }

}

static void MX_ADC3_Init(void)
{

  ADC_ChannelConfTypeDef sConfig = {0};

  /** Common config
  */
  hadc3.Instance = ADC3;
  hadc3.Init.ClockPrescaler = ADC_CLOCK_ASYNC_DIV1;
  hadc3.Init.Resolution = ADC_RESOLUTION_12B;
  hadc3.Init.DataAlign = ADC3_DATAALIGN_RIGHT;
  hadc3.Init.ScanConvMode = ADC_SCAN_DISABLE;
  hadc3.Init.EOCSelection = ADC_EOC_SINGLE_CONV;
  hadc3.Init.LowPowerAutoWait = DISABLE;
  hadc3.Init.ContinuousConvMode = DISABLE;
  hadc3.Init.NbrOfConversion = 1;
  hadc3.Init.DiscontinuousConvMode = DISABLE;
  hadc3.Init.ExternalTrigConv = ADC_SOFTWARE_START;
  hadc3.Init.ExternalTrigConvEdge = ADC_EXTERNALTRIGCONVEDGE_NONE;
  hadc3.Init.DMAContinuousRequests = DISABLE;
  hadc3.Init.SamplingMode = ADC_SAMPLING_MODE_NORMAL;
  hadc3.Init.ConversionDataManagement = ADC_CONVERSIONDATA_DR;
  hadc3.Init.Overrun = ADC_OVR_DATA_PRESERVED;
  hadc3.Init.LeftBitShift = ADC_LEFTBITSHIFT_NONE;
  hadc3.Init.OversamplingMode = DISABLE;
  if (HAL_ADC_Init(&hadc3) != HAL_OK)
  {
    Error_Handler();
  }
  /** Configure Regular Channel
  */
  sConfig.Channel = ADC_CHANNEL_0;
  sConfig.Rank = ADC_REGULAR_RANK_1;
  sConfig.SamplingTime = ADC3_SAMPLETIME_2CYCLES_5;
  sConfig.SingleDiff = ADC_SINGLE_ENDED;
  sConfig.OffsetNumber = ADC_OFFSET_NONE;
  sConfig.Offset = 0;
  sConfig.OffsetSignedSaturation = DISABLE;
  sConfig.OffsetSign = ADC3_OFFSET_SIGN_NEGATIVE;
  sConfig.OffsetSaturation = DISABLE;
  if (HAL_ADC_ConfigChannel(&hadc3, &sConfig) != HAL_OK)
  {
    Error_Handler();
  }

}

static void MX_DAC1_Init(void)
{

  DAC_ChannelConfTypeDef sConfig = {0};

  /** DAC Initialization
  */
  hdac1.Instance = DAC1;
  if (HAL_DAC_Init(&hdac1) != HAL_OK)
  {
    Error_Handler();
  }
  /** DAC channel OUT2 config
  */
  sConfig.DAC_SampleAndHold = DAC_SAMPLEANDHOLD_DISABLE;
  sConfig.DAC_Trigger = DAC_TRIGGER_NONE;
  sConfig.DAC_OutputBuffer = DAC_OUTPUTBUFFER_ENABLE;
  sConfig.DAC_ConnectOnChipPeripheral = DAC_CHIPCONNECT_DISABLE;
  sConfig.DAC_UserTrimming = DAC_TRIMMING_FACTORY;
  if (HAL_DAC_ConfigChannel(&hdac1, &sConfig, DAC_CHANNEL_2) != HAL_OK)
  {
    Error_Handler();
  }

}

static void MX_FDCAN1_Init(void)
{

  hfdcan1.Instance = FDCAN1;
  hfdcan1.Init.FrameFormat = FDCAN_FRAME_CLASSIC;
  hfdcan1.Init.Mode = FDCAN_MODE_NORMAL;
  hfdcan1.Init.AutoRetransmission = DISABLE;
  hfdcan1.Init.TransmitPause = DISABLE;
  hfdcan1.Init.ProtocolException = DISABLE;
  hfdcan1.Init.NominalPrescaler = 1;
  hfdcan1.Init.NominalSyncJumpWidth = 1;
  hfdcan1.Init.NominalTimeSeg1 = 2;
  hfdcan1.Init.NominalTimeSeg2 = 2;
  hfdcan1.Init.DataPrescaler = 1;
  hfdcan1.Init.DataSyncJumpWidth = 1;
  hfdcan1.Init.DataTimeSeg1 = 1;
  hfdcan1.Init.DataTimeSeg2 = 1;
  hfdcan1.Init.MessageRAMOffset = 0;
  hfdcan1.Init.StdFiltersNbr = 0;
  hfdcan1.Init.ExtFiltersNbr = 0;
  hfdcan1.Init.RxFifo0ElmtsNbr = 0;
  hfdcan1.Init.RxFifo0ElmtSize = FDCAN_DATA_BYTES_8;
  hfdcan1.Init.RxFifo1ElmtsNbr = 0;
  hfdcan1.Init.RxFifo1ElmtSize = FDCAN_DATA_BYTES_8;
  hfdcan1.Init.RxBuffersNbr = 0;
  hfdcan1.Init.RxBufferSize = FDCAN_DATA_BYTES_8;
  hfdcan1.Init.TxEventsNbr = 0;
  hfdcan1.Init.TxBuffersNbr = 0;
  hfdcan1.Init.TxFifoQueueElmtsNbr = 0;
  hfdcan1.Init.TxFifoQueueMode = FDCAN_TX_FIFO_OPERATION;
  hfdcan1.Init.TxElmtSize = FDCAN_DATA_BYTES_8;
  if (HAL_FDCAN_Init(&hfdcan1) != HAL_OK)
  {
    Error_Handler();
  }

}

static void MX_FDCAN2_Init(void)
{

  hfdcan2.Instance = FDCAN2;
  hfdcan2.Init.FrameFormat = FDCAN_FRAME_CLASSIC;
  hfdcan2.Init.Mode = FDCAN_MODE_NORMAL;
  hfdcan2.Init.AutoRetransmission = DISABLE;
  hfdcan2.Init.TransmitPause = DISABLE;
  hfdcan2.Init.ProtocolException = DISABLE;
  hfdcan2.Init.NominalPrescaler = 1;
  hfdcan2.Init.NominalSyncJumpWidth = 1;
  hfdcan2.Init.NominalTimeSeg1 = 2;
  hfdcan2.Init.NominalTimeSeg2 = 2;
  hfdcan2.Init.DataPrescaler = 1;
  hfdcan2.Init.DataSyncJumpWidth = 1;
  hfdcan2.Init.DataTimeSeg1 = 1;
  hfdcan2.Init.DataTimeSeg2 = 1;
  hfdcan2.Init.MessageRAMOffset = 0;
  hfdcan2.Init.StdFiltersNbr = 0;
  hfdcan2.Init.ExtFiltersNbr = 0;
  hfdcan2.Init.RxFifo0ElmtsNbr = 0;
  hfdcan2.Init.RxFifo0ElmtSize = FDCAN_DATA_BYTES_8;
  hfdcan2.Init.RxFifo1ElmtsNbr = 0;
  hfdcan2.Init.RxFifo1ElmtSize = FDCAN_DATA_BYTES_8;
  hfdcan2.Init.RxBuffersNbr = 0;
  hfdcan2.Init.RxBufferSize = FDCAN_DATA_BYTES_8;
  hfdcan2.Init.TxEventsNbr = 0;
  hfdcan2.Init.TxBuffersNbr = 0;
  hfdcan2.Init.TxFifoQueueElmtsNbr = 0;
  hfdcan2.Init.TxFifoQueueMode = FDCAN_TX_FIFO_OPERATION;
  hfdcan2.Init.TxElmtSize = FDCAN_DATA_BYTES_8;
  if (HAL_FDCAN_Init(&hfdcan2) != HAL_OK)
  {
    Error_Handler();
  }

}

static void MX_I2C4_Init(void)
{

  hi2c4.Instance = I2C4;
  hi2c4.Init.Timing = 0x60404E72;
  hi2c4.Init.OwnAddress1 = 0;
  hi2c4.Init.AddressingMode = I2C_ADDRESSINGMODE_7BIT;
  hi2c4.Init.DualAddressMode = I2C_DUALADDRESS_DISABLE;
  hi2c4.Init.OwnAddress2 = 0;
  hi2c4.Init.OwnAddress2Masks = I2C_OA2_NOMASK;
  hi2c4.Init.GeneralCallMode = I2C_GENERALCALL_DISABLE;
  hi2c4.Init.NoStretchMode = I2C_NOSTRETCH_DISABLE;
  if (HAL_I2C_Init(&hi2c4) != HAL_OK)
  {
    Error_Handler();
  }
  /** Configure Analogue filter
  */
  if (HAL_I2CEx_ConfigAnalogFilter(&hi2c4, I2C_ANALOGFILTER_ENABLE) != HAL_OK)
  {
    Error_Handler();
  }
  /** Configure Digital filter
  */
  if (HAL_I2CEx_ConfigDigitalFilter(&hi2c4, 0) != HAL_OK)
  {
    Error_Handler();
  }

}

static void MX_RTC_Init(void)
{

  RTC_TimeTypeDef sTime = {0};
  RTC_DateTypeDef sDate = {0};

  /** Initialize RTC Only
  */
  hrtc.Instance = RTC;
  hrtc.Init.HourFormat = RTC_HOURFORMAT_24;
  hrtc.Init.AsynchPrediv = 127;
  hrtc.Init.SynchPrediv = 255;
  hrtc.Init.OutPut = RTC_OUTPUT_DISABLE;
  hrtc.Init.OutPutPolarity = RTC_OUTPUT_POLARITY_HIGH;
  hrtc.Init.OutPutType = RTC_OUTPUT_TYPE_OPENDRAIN;
  hrtc.Init.OutPutRemap = RTC_OUTPUT_REMAP_NONE;
  if (HAL_RTC_Init(&hrtc) != HAL_OK)
  {
    Error_Handler();
  }

  /** Initialize RTC and set the Time and Date
  */
  sTime.Hours = 0x22;
  sTime.Minutes = 0x22;
  sTime.Seconds = 0x22;
  sTime.DayLightSaving = RTC_DAYLIGHTSAVING_NONE;
  sTime.StoreOperation = RTC_STOREOPERATION_RESET;
  if (HAL_RTC_SetTime(&hrtc, &sTime, RTC_FORMAT_BCD) != HAL_OK)
  {
    Error_Handler();
  }
  sDate.WeekDay = RTC_WEEKDAY_THURSDAY;
  sDate.Month = RTC_MONTH_FEBRUARY;
  sDate.Date = 0x10;
  sDate.Year = 0x22;

  if (HAL_RTC_SetDate(&hrtc, &sDate, RTC_FORMAT_BCD) != HAL_OK)
  {
    Error_Handler();
  }

}

static void MX_TIM4_Init(void)
{

  TIM_MasterConfigTypeDef sMasterConfig = {0};
  TIM_OC_InitTypeDef sConfigOC = {0};

  htim4.Instance = TIM4;
  htim4.Init.Prescaler = 0;
  htim4.Init.CounterMode = TIM_COUNTERMODE_UP;
  htim4.Init.Period = 65535;
  htim4.Init.ClockDivision = TIM_CLOCKDIVISION_DIV1;
  htim4.Init.AutoReloadPreload = TIM_AUTORELOAD_PRELOAD_DISABLE;
  if (HAL_TIM_PWM_Init(&htim4) != HAL_OK)
  {
    Error_Handler();
  }
  sMasterConfig.MasterOutputTrigger = TIM_TRGO_RESET;
  sMasterConfig.MasterSlaveMode = TIM_MASTERSLAVEMODE_DISABLE;
  if (HAL_TIMEx_MasterConfigSynchronization(&htim4, &sMasterConfig) != HAL_OK)
  {
    Error_Handler();
  }
  sConfigOC.OCMode = TIM_OCMODE_PWM1;
  sConfigOC.Pulse = 0;
  sConfigOC.OCPolarity = TIM_OCPOLARITY_HIGH;
  sConfigOC.OCFastMode = TIM_OCFAST_DISABLE;
  if (HAL_TIM_PWM_ConfigChannel(&htim4, &sConfigOC, TIM_CHANNEL_2) != HAL_OK)
  {
    Error_Handler();
  }
  if (HAL_TIM_PWM_ConfigChannel(&htim4, &sConfigOC, TIM_CHANNEL_3) != HAL_OK)
  {
    Error_Handler();
  }
  HAL_TIM_MspPostInit(&htim4);

}

static void MX_TIM7_Init(void)
{

  TIM_MasterConfigTypeDef sMasterConfig = {0};

  htim7.Instance = TIM7;
  htim7.Init.Prescaler = 27500-1;
  htim7.Init.CounterMode = TIM_COUNTERMODE_UP;
  htim7.Init.Period = 500-1;
  htim7.Init.AutoReloadPreload = TIM_AUTORELOAD_PRELOAD_DISABLE;
  if (HAL_TIM_Base_Init(&htim7) != HAL_OK)
  {
    Error_Handler();
  }
  sMasterConfig.MasterOutputTrigger = TIM_TRGO_RESET;
  sMasterConfig.MasterSlaveMode = TIM_MASTERSLAVEMODE_DISABLE;
  if (HAL_TIMEx_MasterConfigSynchronization(&htim7, &sMasterConfig) != HAL_OK)
  {
    Error_Handler();
  }

}

static void MX_TIM13_Init(void)
{

  htim13.Instance = TIM13;
  htim13.Init.Prescaler = 27500 -1;
  htim13.Init.CounterMode = TIM_COUNTERMODE_UP;
  htim13.Init.Period = 1500-1;
  htim13.Init.ClockDivision = TIM_CLOCKDIVISION_DIV1;
  htim13.Init.AutoReloadPreload = TIM_AUTORELOAD_PRELOAD_DISABLE;
  if (HAL_TIM_Base_Init(&htim13) != HAL_OK)
  {
    Error_Handler();
  }

}

static void MX_TIM14_Init(void)
{

  htim14.Instance = TIM14;
  htim14.Init.Prescaler = 2750-1;
  htim14.Init.CounterMode = TIM_COUNTERMODE_UP;
  htim14.Init.Period = 65535;
  htim14.Init.ClockDivision = TIM_CLOCKDIVISION_DIV1;
  htim14.Init.AutoReloadPreload = TIM_AUTORELOAD_PRELOAD_DISABLE;
  if (HAL_TIM_Base_Init(&htim14) != HAL_OK)
  {
    Error_Handler();
  }

}

static void MX_TIM16_Init(void)
{

  htim16.Instance = TIM16;
  htim16.Init.Prescaler = 27500-1;
  htim16.Init.CounterMode = TIM_COUNTERMODE_UP;
  htim16.Init.Period = 3500-1;
  htim16.Init.ClockDivision = TIM_CLOCKDIVISION_DIV1;
  htim16.Init.RepetitionCounter = 0;
  htim16.Init.AutoReloadPreload = TIM_AUTORELOAD_PRELOAD_DISABLE;
  if (HAL_TIM_Base_Init(&htim16) != HAL_OK)
  {
    Error_Handler();
  }

}

static void MX_TIM17_Init(void)
{

  htim17.Instance = TIM17;
  htim17.Init.Prescaler = 27500-1;
  htim17.Init.CounterMode = TIM_COUNTERMODE_UP;
  htim17.Init.Period = 5000-1;
  htim17.Init.ClockDivision = TIM_CLOCKDIVISION_DIV1;
  htim17.Init.RepetitionCounter = 0;
  htim17.Init.AutoReloadPreload = TIM_AUTORELOAD_PRELOAD_DISABLE;
  if (HAL_TIM_Base_Init(&htim17) != HAL_OK)
  {
    Error_Handler();
  }

}

static void MX_USART1_UART_Init(void)
{

  huart1.Instance = USART1;
  huart1.Init.BaudRate = 115200;
  huart1.Init.WordLength = UART_WORDLENGTH_8B;
  huart1.Init.StopBits = UART_STOPBITS_1;
  huart1.Init.Parity = UART_PARITY_NONE;
  huart1.Init.Mode = UART_MODE_TX_RX;
  huart1.Init.HwFlowCtl = UART_HWCONTROL_NONE;
  huart1.Init.OverSampling = UART_OVERSAMPLING_16;
  huart1.Init.OneBitSampling = UART_ONE_BIT_SAMPLE_DISABLE;
  huart1.Init.ClockPrescaler = UART_PRESCALER_DIV1;
  huart1.AdvancedInit.AdvFeatureInit = UART_ADVFEATURE_NO_INIT;
  if (HAL_UART_Init(&huart1) != HAL_OK)
  {
    Error_Handler();
  }
  if (HAL_UARTEx_SetTxFifoThreshold(&huart1, UART_TXFIFO_THRESHOLD_1_8) != HAL_OK)
  {
    Error_Handler();
  }
  if (HAL_UARTEx_SetRxFifoThreshold(&huart1, UART_RXFIFO_THRESHOLD_1_8) != HAL_OK)
  {
    Error_Handler();
  }
  if (HAL_UARTEx_DisableFifoMode(&huart1) != HAL_OK)
  {
    Error_Handler();
  }

}

static void MX_USART3_UART_Init(void)
{

  huart3.Instance = USART3;
  huart3.Init.BaudRate = 115200;
  huart3.Init.WordLength = UART_WORDLENGTH_8B;
  huart3.Init.StopBits = UART_STOPBITS_1;
  huart3.Init.Parity = UART_PARITY_NONE;
  huart3.Init.Mode = UART_MODE_TX_RX;
  huart3.Init.HwFlowCtl = UART_HWCONTROL_NONE;
  huart3.Init.OverSampling = UART_OVERSAMPLING_16;
  huart3.Init.OneBitSampling = UART_ONE_BIT_SAMPLE_DISABLE;
  huart3.Init.ClockPrescaler = UART_PRESCALER_DIV1;
  huart3.AdvancedInit.AdvFeatureInit = UART_ADVFEATURE_NO_INIT;
  if (HAL_UART_Init(&huart3) != HAL_OK)
  {
    Error_Handler();
  }
  if (HAL_UARTEx_SetTxFifoThreshold(&huart3, UART_TXFIFO_THRESHOLD_1_8) != HAL_OK)
  {
    Error_Handler();
  }
  if (HAL_UARTEx_SetRxFifoThreshold(&huart3, UART_RXFIFO_THRESHOLD_1_8) != HAL_OK)
  {
    Error_Handler();
  }
  if (HAL_UARTEx_DisableFifoMode(&huart3) != HAL_OK)
  {
    Error_Handler();
  }

}

static void MX_GPIO_Init(void)
{
  GPIO_InitTypeDef GPIO_InitStruct = {0};

  /* GPIO Ports Clock Enable */
  __HAL_RCC_GPIOB_CLK_ENABLE();
  __HAL_RCC_GPIOG_CLK_ENABLE();
  __HAL_RCC_GPIOD_CLK_ENABLE();
  __HAL_RCC_GPIOA_CLK_ENABLE();
  __HAL_RCC_GPIOE_CLK_ENABLE();
  __HAL_RCC_GPIOC_CLK_ENABLE();
  __HAL_RCC_GPIOH_CLK_ENABLE();
  __HAL_RCC_GPIOF_CLK_ENABLE();

  /*Configure GPIO pin Output Level */
  HAL_GPIO_WritePin(GPIOD, Detectn_Pin|MAIN_N_RELAY_Pin|LCD_DISP_Pin, GPIO_PIN_RESET);

  /*Configure GPIO pin Output Level */
  HAL_GPIO_WritePin(GPIOE, ARD_D8_Pin|PRE_IGBT_Pin|STMOD_17_Pin|STMOD_19_Pin
                          |STMOD_18_Pin, GPIO_PIN_RESET);

  /*Configure GPIO pin Output Level */
  HAL_GPIO_WritePin(GPIOG, MP_IGBT_Pin|LCD_BL_CTRL_Pin|MAIN_N_IGBT_Pin|MEMS_LED_Pin
                          |MAIN_P_IGBT_Pin|ARD_D2_Pin, GPIO_PIN_RESET);

  /*Configure GPIO pin Output Level */
  HAL_GPIO_WritePin(GPIOA, MP_Relay_Pin|MAIN_P_RELAY_Pin, GPIO_PIN_RESET);

  /*Configure GPIO pin Output Level */
  HAL_GPIO_WritePin(GPIOF, PC_IGBT_Pin|STMOD_20_Pin, GPIO_PIN_RESET);

  /*Configure GPIO pin Output Level */
  HAL_GPIO_WritePin(GPIOC, MN_IGBT_Pin|MN_Relay_Pin, GPIO_PIN_RESET);

  /*Configure GPIO pin Output Level */
  HAL_GPIO_WritePin(GPIOH, LCD_RST_Pin|USB_FS_PWR_EN_Pin, GPIO_PIN_RESET);

  /*Configure GPIO pins : LCD_B6_Pin LCD_B7_Pin LCD_G0_Pin LCD_G1_Pin */
  GPIO_InitStruct.Pin = LCD_B6_Pin|LCD_B7_Pin|LCD_G0_Pin|LCD_G1_Pin;
  GPIO_InitStruct.Mode = GPIO_MODE_AF_PP;
  GPIO_InitStruct.Pull = GPIO_NOPULL;
  GPIO_InitStruct.Speed = GPIO_SPEED_FREQ_LOW;
  GPIO_InitStruct.Alternate = GPIO_AF14_LTDC;
  HAL_GPIO_Init(GPIOB, &GPIO_InitStruct);

  /*Configure GPIO pins : OCSPI2_IO7_Pin OCSPI2_IO5_Pin OCSPI2_IO4_Pin */
  GPIO_InitStruct.Pin = OCSPI2_IO7_Pin|OCSPI2_IO5_Pin|OCSPI2_IO4_Pin;
  GPIO_InitStruct.Mode = GPIO_MODE_AF_PP;
  GPIO_InitStruct.Pull = GPIO_NOPULL;
  GPIO_InitStruct.Speed = GPIO_SPEED_FREQ_VERY_HIGH;
  GPIO_InitStruct.Alternate = GPIO_AF9_OCTOSPIM_P2;
  HAL_GPIO_Init(GPIOG, &GPIO_InitStruct);

  /*Configure GPIO pin : OCSPI1_IO6_Pin */
  GPIO_InitStruct.Pin = OCSPI1_IO6_Pin;
  GPIO_InitStruct.Mode = GPIO_MODE_AF_PP;
  GPIO_InitStruct.Pull = GPIO_NOPULL;
  GPIO_InitStruct.Speed = GPIO_SPEED_FREQ_VERY_HIGH;
  GPIO_InitStruct.Alternate = GPIO_AF9_OCTOSPIM_P1;
  HAL_GPIO_Init(OCSPI1_IO6_GPIO_Port, &GPIO_InitStruct);

  /*Configure GPIO pins : LCD_G7_Pin LCD_B1_Pin LCD_B2_Pin */
  GPIO_InitStruct.Pin = LCD_G7_Pin|LCD_B1_Pin|LCD_B2_Pin;
  GPIO_InitStruct.Mode = GPIO_MODE_AF_PP;
  GPIO_InitStruct.Pull = GPIO_NOPULL;
  GPIO_InitStruct.Speed = GPIO_SPEED_FREQ_LOW;
  GPIO_InitStruct.Alternate = GPIO_AF14_LTDC;
  HAL_GPIO_Init(GPIOD, &GPIO_InitStruct);

  /*Configure GPIO pins : Detectn_Pin MAIN_N_RELAY_Pin LCD_DISP_Pin */
  GPIO_InitStruct.Pin = Detectn_Pin|MAIN_N_RELAY_Pin|LCD_DISP_Pin;
  GPIO_InitStruct.Mode = GPIO_MODE_OUTPUT_PP;
  GPIO_InitStruct.Pull = GPIO_NOPULL;
  GPIO_InitStruct.Speed = GPIO_SPEED_FREQ_LOW;
  HAL_GPIO_Init(GPIOD, &GPIO_InitStruct);

  /*Configure GPIO pins : SAI4_D2_Pin SAI4_CK2_Pin */
  GPIO_InitStruct.Pin = SAI4_D2_Pin|SAI4_CK2_Pin;
  GPIO_InitStruct.Mode = GPIO_MODE_AF_PP;
  GPIO_InitStruct.Pull = GPIO_NOPULL;
  GPIO_InitStruct.Speed = GPIO_SPEED_FREQ_LOW;
  GPIO_InitStruct.Alternate = GPIO_AF10_SAI4;
  HAL_GPIO_Init(GPIOE, &GPIO_InitStruct);

  /*Configure GPIO pins : ARD_D8_Pin PRE_IGBT_Pin STMOD_17_Pin STMOD_19_Pin
                           STMOD_18_Pin */
  GPIO_InitStruct.Pin = ARD_D8_Pin|PRE_IGBT_Pin|STMOD_17_Pin|STMOD_19_Pin
                          |STMOD_18_Pin;
  GPIO_InitStruct.Mode = GPIO_MODE_OUTPUT_PP;
  GPIO_InitStruct.Pull = GPIO_NOPULL;
  GPIO_InitStruct.Speed = GPIO_SPEED_FREQ_LOW;
  HAL_GPIO_Init(GPIOE, &GPIO_InitStruct);

  /*Configure GPIO pins : LCD_R0_Pin LCD_R6_Pin LCD_B4_Pin LCD_DE_Pin
                           LCD_R7_Pin LCD_G3_Pin */
  GPIO_InitStruct.Pin = LCD_R0_Pin|LCD_R6_Pin|LCD_B4_Pin|LCD_DE_Pin
                          |LCD_R7_Pin|LCD_G3_Pin;
  GPIO_InitStruct.Mode = GPIO_MODE_AF_PP;
  GPIO_InitStruct.Pull = GPIO_NOPULL;
  GPIO_InitStruct.Speed = GPIO_SPEED_FREQ_LOW;
  GPIO_InitStruct.Alternate = GPIO_AF14_LTDC;
  HAL_GPIO_Init(GPIOE, &GPIO_InitStruct);

  /*Configure GPIO pins : MP_IGBT_Pin LCD_BL_CTRL_Pin MAIN_N_IGBT_Pin MEMS_LED_Pin
                           MAIN_P_IGBT_Pin ARD_D2_Pin */
  GPIO_InitStruct.Pin = MP_IGBT_Pin|LCD_BL_CTRL_Pin|MAIN_N_IGBT_Pin|MEMS_LED_Pin
                          |MAIN_P_IGBT_Pin|ARD_D2_Pin;
  GPIO_InitStruct.Mode = GPIO_MODE_OUTPUT_PP;
  GPIO_InitStruct.Pull = GPIO_NOPULL;
  GPIO_InitStruct.Speed = GPIO_SPEED_FREQ_LOW;
  HAL_GPIO_Init(GPIOG, &GPIO_InitStruct);

  /*Configure GPIO pins : OCSPI1_IO7_Pin OCSPI1_IO5_Pin OCSPI1_IO4_Pin */
  GPIO_InitStruct.Pin = OCSPI1_IO7_Pin|OCSPI1_IO5_Pin|OCSPI1_IO4_Pin;
  GPIO_InitStruct.Mode = GPIO_MODE_AF_PP;
  GPIO_InitStruct.Pull = GPIO_NOPULL;
  GPIO_InitStruct.Speed = GPIO_SPEED_FREQ_VERY_HIGH;
  GPIO_InitStruct.Alternate = GPIO_AF10_OCTOSPIM_P1;
  HAL_GPIO_Init(GPIOD, &GPIO_InitStruct);

  /*Configure GPIO pin : SDIO1_CMD_Pin */
  GPIO_InitStruct.Pin = SDIO1_CMD_Pin;
  GPIO_InitStruct.Mode = GPIO_MODE_AF_PP;
  GPIO_InitStruct.Pull = GPIO_NOPULL;
  GPIO_InitStruct.Speed = GPIO_SPEED_FREQ_VERY_HIGH;
  GPIO_InitStruct.Alternate = GPIO_AF12_SDMMC1;
  HAL_GPIO_Init(SDIO1_CMD_GPIO_Port, &GPIO_InitStruct);

  /*Configure GPIO pins : SDIO1_CK_Pin SDIO1_D3_Pin SDIO1_D2_Pin SDIO1_D0_Pin
                           SDIO1_D1_Pin */
  GPIO_InitStruct.Pin = SDIO1_CK_Pin|SDIO1_D3_Pin|SDIO1_D2_Pin|SDIO1_D0_Pin
                          |SDIO1_D1_Pin;
  GPIO_InitStruct.Mode = GPIO_MODE_AF_PP;
  GPIO_InitStruct.Pull = GPIO_NOPULL;
  GPIO_InitStruct.Speed = GPIO_SPEED_FREQ_VERY_HIGH;
  GPIO_InitStruct.Alternate = GPIO_AF12_SDMMC1;
  HAL_GPIO_Init(GPIOC, &GPIO_InitStruct);

  /*Configure GPIO pin : LCD_B3_Pin */
  GPIO_InitStruct.Pin = LCD_B3_Pin;
  GPIO_InitStruct.Mode = GPIO_MODE_AF_PP;
  GPIO_InitStruct.Pull = GPIO_NOPULL;
  GPIO_InitStruct.Speed = GPIO_SPEED_FREQ_LOW;
  GPIO_InitStruct.Alternate = GPIO_AF13_LTDC;
  HAL_GPIO_Init(LCD_B3_GPIO_Port, &GPIO_InitStruct);

  /*Configure GPIO pins : USB_FS_DP_Pin USB_FS_DM_Pin */
  GPIO_InitStruct.Pin = USB_FS_DP_Pin|USB_FS_DM_Pin;
  GPIO_InitStruct.Mode = GPIO_MODE_AF_PP;
  GPIO_InitStruct.Pull = GPIO_NOPULL;
  GPIO_InitStruct.Speed = GPIO_SPEED_FREQ_LOW;
  HAL_GPIO_Init(GPIOA, &GPIO_InitStruct);

  /*Configure GPIO pin : Button_2_Pin */
  GPIO_InitStruct.Pin = Button_2_Pin;
  GPIO_InitStruct.Mode = GPIO_MODE_IT_RISING;
  GPIO_InitStruct.Pull = GPIO_NOPULL;
  HAL_GPIO_Init(Button_2_GPIO_Port, &GPIO_InitStruct);

  /*Configure GPIO pin : OCSPI1_IO2_Pin */
  GPIO_InitStruct.Pin = OCSPI1_IO2_Pin;
  GPIO_InitStruct.Mode = GPIO_MODE_AF_PP;
  GPIO_InitStruct.Pull = GPIO_NOPULL;
  GPIO_InitStruct.Speed = GPIO_SPEED_FREQ_VERY_HIGH;
  GPIO_InitStruct.Alternate = GPIO_AF9_OCTOSPIM_P1;
  HAL_GPIO_Init(OCSPI1_IO2_GPIO_Port, &GPIO_InitStruct);

  /*Configure GPIO pins : LCD_B0_Pin LCD_CLK_Pin */
  GPIO_InitStruct.Pin = LCD_B0_Pin|LCD_CLK_Pin;
  GPIO_InitStruct.Mode = GPIO_MODE_AF_PP;
  GPIO_InitStruct.Pull = GPIO_NOPULL;
  GPIO_InitStruct.Speed = GPIO_SPEED_FREQ_LOW;
  GPIO_InitStruct.Alternate = GPIO_AF14_LTDC;
  HAL_GPIO_Init(GPIOG, &GPIO_InitStruct);

  /*Configure GPIO pins : OCSPI2_IO6_Pin OCSPI2_NCS_Pin */
  GPIO_InitStruct.Pin = OCSPI2_IO6_Pin|OCSPI2_NCS_Pin;
  GPIO_InitStruct.Mode = GPIO_MODE_AF_PP;
  GPIO_InitStruct.Pull = GPIO_NOPULL;
  GPIO_InitStruct.Speed = GPIO_SPEED_FREQ_VERY_HIGH;
  GPIO_InitStruct.Alternate = GPIO_AF3_OCTOSPIM_P2;
  HAL_GPIO_Init(GPIOG, &GPIO_InitStruct);

  /*Configure GPIO pin : USB_FS_ID_Pin */
  GPIO_InitStruct.Pin = USB_FS_ID_Pin;
  GPIO_InitStruct.Mode = GPIO_MODE_AF_PP;
  GPIO_InitStruct.Pull = GPIO_NOPULL;
  GPIO_InitStruct.Speed = GPIO_SPEED_FREQ_LOW;
  GPIO_InitStruct.Alternate = GPIO_AF10_OTG1_HS;
  HAL_GPIO_Init(USB_FS_ID_GPIO_Port, &GPIO_InitStruct);

  /*Configure GPIO pins : LCD_G4_Pin LCD_R5_Pin LCD_R3_Pin LCD_R2_Pin
                           LCD_R4_Pin LCD_R1_Pin */
  GPIO_InitStruct.Pin = LCD_G4_Pin|LCD_R5_Pin|LCD_R3_Pin|LCD_R2_Pin
                          |LCD_R4_Pin|LCD_R1_Pin;
  GPIO_InitStruct.Mode = GPIO_MODE_AF_PP;
  GPIO_InitStruct.Pull = GPIO_NOPULL;
  GPIO_InitStruct.Speed = GPIO_SPEED_FREQ_LOW;
  GPIO_InitStruct.Alternate = GPIO_AF14_LTDC;
  HAL_GPIO_Init(GPIOH, &GPIO_InitStruct);

  /*Configure GPIO pins : MP_Relay_Pin MAIN_P_RELAY_Pin */
  GPIO_InitStruct.Pin = MP_Relay_Pin|MAIN_P_RELAY_Pin;
  GPIO_InitStruct.Mode = GPIO_MODE_OUTPUT_PP;
  GPIO_InitStruct.Pull = GPIO_NOPULL;
  GPIO_InitStruct.Speed = GPIO_SPEED_FREQ_LOW;
  HAL_GPIO_Init(GPIOA, &GPIO_InitStruct);

  /*Configure GPIO pins : LCD_G6_Pin LCD_HSYNC_Pin */
  GPIO_InitStruct.Pin = LCD_G6_Pin|LCD_HSYNC_Pin;
  GPIO_InitStruct.Mode = GPIO_MODE_AF_PP;
  GPIO_InitStruct.Pull = GPIO_NOPULL;
  GPIO_InitStruct.Speed = GPIO_SPEED_FREQ_LOW;
  GPIO_InitStruct.Alternate = GPIO_AF14_LTDC;
  HAL_GPIO_Init(GPIOC, &GPIO_InitStruct);

  /*Configure GPIO pin : SAI1_SD_A_Pin */
  GPIO_InitStruct.Pin = SAI1_SD_A_Pin;
  GPIO_InitStruct.Mode = GPIO_MODE_AF_PP;
  GPIO_InitStruct.Pull = GPIO_NOPULL;
  GPIO_InitStruct.Speed = GPIO_SPEED_FREQ_LOW;
  GPIO_InitStruct.Alternate = GPIO_AF6_SAI1;
  HAL_GPIO_Init(SAI1_SD_A_GPIO_Port, &GPIO_InitStruct);

  /*Configure GPIO pins : OCSPI2_IO1_Pin OCSPI2_IO0_Pin OCSPI2_IO2_Pin OCSPI2_CLK_Pin
                           OCSPI2_IO3_Pin OCSPI2_DQS_Pin */
  GPIO_InitStruct.Pin = OCSPI2_IO1_Pin|OCSPI2_IO0_Pin|OCSPI2_IO2_Pin|OCSPI2_CLK_Pin
                          |OCSPI2_IO3_Pin|OCSPI2_DQS_Pin;
  GPIO_InitStruct.Mode = GPIO_MODE_AF_PP;
  GPIO_InitStruct.Pull = GPIO_NOPULL;
  GPIO_InitStruct.Speed = GPIO_SPEED_FREQ_VERY_HIGH;
  GPIO_InitStruct.Alternate = GPIO_AF9_OCTOSPIM_P2;
  HAL_GPIO_Init(GPIOF, &GPIO_InitStruct);

  /*Configure GPIO pin : OCSPI1_NCS_Pin */
  GPIO_InitStruct.Pin = OCSPI1_NCS_Pin;
  GPIO_InitStruct.Mode = GPIO_MODE_AF_PP;
  GPIO_InitStruct.Pull = GPIO_NOPULL;
  GPIO_InitStruct.Speed = GPIO_SPEED_FREQ_VERY_HIGH;
  GPIO_InitStruct.Alternate = GPIO_AF10_OCTOSPIM_P1;
  HAL_GPIO_Init(OCSPI1_NCS_GPIO_Port, &GPIO_InitStruct);

  /*Configure GPIO pin : CTP_INT_Pin */
  GPIO_InitStruct.Pin = CTP_INT_Pin;
  GPIO_InitStruct.Mode = GPIO_MODE_IT_RISING;
  GPIO_InitStruct.Pull = GPIO_NOPULL;
  HAL_GPIO_Init(CTP_INT_GPIO_Port, &GPIO_InitStruct);

  /*Configure GPIO pins : SAI1_SD_B_Pin SAI1_SCK_B_Pin SAI1_FS_B_Pin */
  GPIO_InitStruct.Pin = SAI1_SD_B_Pin|SAI1_SCK_B_Pin|SAI1_FS_B_Pin;
  GPIO_InitStruct.Mode = GPIO_MODE_AF_PP;
  GPIO_InitStruct.Pull = GPIO_NOPULL;
  GPIO_InitStruct.Speed = GPIO_SPEED_FREQ_LOW;
  GPIO_InitStruct.Alternate = GPIO_AF6_SAI1;
  HAL_GPIO_Init(GPIOF, &GPIO_InitStruct);

  /*Configure GPIO pin : uSD_Detect_Pin */
  GPIO_InitStruct.Pin = uSD_Detect_Pin;
  GPIO_InitStruct.Mode = GPIO_MODE_IT_RISING;
  GPIO_InitStruct.Pull = GPIO_NOPULL;
  HAL_GPIO_Init(uSD_Detect_GPIO_Port, &GPIO_InitStruct);

  /*Configure GPIO pins : OCSPI1_IO3_Pin OCSPI1_IO0_Pin OCSPI1_IO1_Pin */
  GPIO_InitStruct.Pin = OCSPI1_IO3_Pin|OCSPI1_IO0_Pin|OCSPI1_IO1_Pin;
  GPIO_InitStruct.Mode = GPIO_MODE_AF_PP;
  GPIO_InitStruct.Pull = GPIO_NOPULL;
  GPIO_InitStruct.Speed = GPIO_SPEED_FREQ_VERY_HIGH;
  GPIO_InitStruct.Alternate = GPIO_AF9_OCTOSPIM_P1;
  HAL_GPIO_Init(GPIOD, &GPIO_InitStruct);

  /*Configure GPIO pins : PC_IGBT_Pin STMOD_20_Pin */
  GPIO_InitStruct.Pin = PC_IGBT_Pin|STMOD_20_Pin;
  GPIO_InitStruct.Mode = GPIO_MODE_OUTPUT_PP;
  GPIO_InitStruct.Pull = GPIO_NOPULL;
  GPIO_InitStruct.Speed = GPIO_SPEED_FREQ_LOW;
  HAL_GPIO_Init(GPIOF, &GPIO_InitStruct);

  /*Configure GPIO pin : OCSPI1_CLK_Pin */
  GPIO_InitStruct.Pin = OCSPI1_CLK_Pin;
  GPIO_InitStruct.Mode = GPIO_MODE_AF_PP;
  GPIO_InitStruct.Pull = GPIO_NOPULL;
  GPIO_InitStruct.Speed = GPIO_SPEED_FREQ_VERY_HIGH;
  GPIO_InitStruct.Alternate = GPIO_AF9_OCTOSPIM_P1;
  HAL_GPIO_Init(OCSPI1_CLK_GPIO_Port, &GPIO_InitStruct);

  /*Configure GPIO pins : RMII_MDC_Pin RMII_RXD1_Pin RMII_RXD0_Pin */
  GPIO_InitStruct.Pin = RMII_MDC_Pin|RMII_RXD1_Pin|RMII_RXD0_Pin;
  GPIO_InitStruct.Mode = GPIO_MODE_AF_PP;
  GPIO_InitStruct.Pull = GPIO_NOPULL;
  GPIO_InitStruct.Speed = GPIO_SPEED_FREQ_LOW;
  GPIO_InitStruct.Alternate = GPIO_AF11_ETH;
  HAL_GPIO_Init(GPIOC, &GPIO_InitStruct);

  /*Configure GPIO pins : RMII_TXD1_Pin RMII_TXD0_Pin RMII_RX_ER_Pin RMII_TX_EN_Pin */
  GPIO_InitStruct.Pin = RMII_TXD1_Pin|RMII_TXD0_Pin|RMII_RX_ER_Pin|RMII_TX_EN_Pin;
  GPIO_InitStruct.Mode = GPIO_MODE_AF_PP;
  GPIO_InitStruct.Pull = GPIO_NOPULL;
  GPIO_InitStruct.Speed = GPIO_SPEED_FREQ_LOW;
  GPIO_InitStruct.Alternate = GPIO_AF11_ETH;
  HAL_GPIO_Init(GPIOB, &GPIO_InitStruct);

  /*Configure GPIO pins : MN_IGBT_Pin MN_Relay_Pin */
  GPIO_InitStruct.Pin = MN_IGBT_Pin|MN_Relay_Pin;
  GPIO_InitStruct.Mode = GPIO_MODE_OUTPUT_PP;
  GPIO_InitStruct.Pull = GPIO_NOPULL;
  GPIO_InitStruct.Speed = GPIO_SPEED_FREQ_LOW;
  HAL_GPIO_Init(GPIOC, &GPIO_InitStruct);

  /*Configure GPIO pin : SPI5_MISO_Pin */
  GPIO_InitStruct.Pin = SPI5_MISO_Pin;
  GPIO_InitStruct.Mode = GPIO_MODE_AF_PP;
  GPIO_InitStruct.Pull = GPIO_NOPULL;
  GPIO_InitStruct.Speed = GPIO_SPEED_FREQ_LOW;
  GPIO_InitStruct.Alternate = GPIO_AF5_SPI5;
  HAL_GPIO_Init(SPI5_MISO_GPIO_Port, &GPIO_InitStruct);

  /*Configure GPIO pins : LCD_B5_Pin LCD_VSYNC_Pin */
  GPIO_InitStruct.Pin = LCD_B5_Pin|LCD_VSYNC_Pin;
  GPIO_InitStruct.Mode = GPIO_MODE_AF_PP;
  GPIO_InitStruct.Pull = GPIO_NOPULL;
  GPIO_InitStruct.Speed = GPIO_SPEED_FREQ_LOW;
  GPIO_InitStruct.Alternate = GPIO_AF14_LTDC;
  HAL_GPIO_Init(GPIOA, &GPIO_InitStruct);

  /*Configure GPIO pins : RMII_CRS_DV_Pin RMII_REF_CLK_Pin RMII_MDIO_Pin */
  GPIO_InitStruct.Pin = RMII_CRS_DV_Pin|RMII_REF_CLK_Pin|RMII_MDIO_Pin;
  GPIO_InitStruct.Mode = GPIO_MODE_AF_PP;
  GPIO_InitStruct.Pull = GPIO_NOPULL;
  GPIO_InitStruct.Speed = GPIO_SPEED_FREQ_LOW;
  GPIO_InitStruct.Alternate = GPIO_AF11_ETH;
  HAL_GPIO_Init(GPIOA, &GPIO_InitStruct);

  /*Configure GPIO pin : SPI5_MOSI_Pin */
  GPIO_InitStruct.Pin = SPI5_MOSI_Pin;
  GPIO_InitStruct.Mode = GPIO_MODE_AF_PP;
  GPIO_InitStruct.Pull = GPIO_NOPULL;
  GPIO_InitStruct.Speed = GPIO_SPEED_FREQ_LOW;
  GPIO_InitStruct.Alternate = GPIO_AF5_SPI5;
  HAL_GPIO_Init(SPI5_MOSI_GPIO_Port, &GPIO_InitStruct);

  /*Configure GPIO pin : Audio_Int_Pin */
  GPIO_InitStruct.Pin = Audio_Int_Pin;
  GPIO_InitStruct.Mode = GPIO_MODE_IT_RISING;
  GPIO_InitStruct.Pull = GPIO_NOPULL;
  HAL_GPIO_Init(Audio_Int_GPIO_Port, &GPIO_InitStruct);

  /*Configure GPIO pin : STMOD_11_INT_Pin */
  GPIO_InitStruct.Pin = STMOD_11_INT_Pin;
  GPIO_InitStruct.Mode = GPIO_MODE_IT_RISING;
  GPIO_InitStruct.Pull = GPIO_NOPULL;
  HAL_GPIO_Init(STMOD_11_INT_GPIO_Port, &GPIO_InitStruct);

  /*Configure GPIO pin : LCD_G5_Pin */
  GPIO_InitStruct.Pin = LCD_G5_Pin;
  GPIO_InitStruct.Mode = GPIO_MODE_AF_PP;
  GPIO_InitStruct.Pull = GPIO_NOPULL;
  GPIO_InitStruct.Speed = GPIO_SPEED_FREQ_LOW;
  GPIO_InitStruct.Alternate = GPIO_AF9_LTDC;
  HAL_GPIO_Init(LCD_G5_GPIO_Port, &GPIO_InitStruct);

  /*Configure GPIO pin : OCSPI1_DQS_Pin */
  GPIO_InitStruct.Pin = OCSPI1_DQS_Pin;
  GPIO_InitStruct.Mode = GPIO_MODE_AF_PP;
  GPIO_InitStruct.Pull = GPIO_NOPULL;
  GPIO_InitStruct.Speed = GPIO_SPEED_FREQ_VERY_HIGH;
  GPIO_InitStruct.Alternate = GPIO_AF10_OCTOSPIM_P1;
  HAL_GPIO_Init(OCSPI1_DQS_GPIO_Port, &GPIO_InitStruct);

  /*Configure GPIO pins : LCD_RST_Pin USB_FS_PWR_EN_Pin */
  GPIO_InitStruct.Pin = LCD_RST_Pin|USB_FS_PWR_EN_Pin;
  GPIO_InitStruct.Mode = GPIO_MODE_OUTPUT_PP;
  GPIO_InitStruct.Pull = GPIO_NOPULL;
  GPIO_InitStruct.Speed = GPIO_SPEED_FREQ_LOW;
  HAL_GPIO_Init(GPIOH, &GPIO_InitStruct);

  /* EXTI interrupt init*/
  HAL_NVIC_SetPriority(EXTI15_10_IRQn, 0, 0);
  HAL_NVIC_EnableIRQ(EXTI15_10_IRQn);

}

void Error_Handler(void)
{
  __disable_irq();
  while (1)
  {
  }
}

/************************ (C) COPYRIGHT STMicroelectronics *****END OF FILE****/
